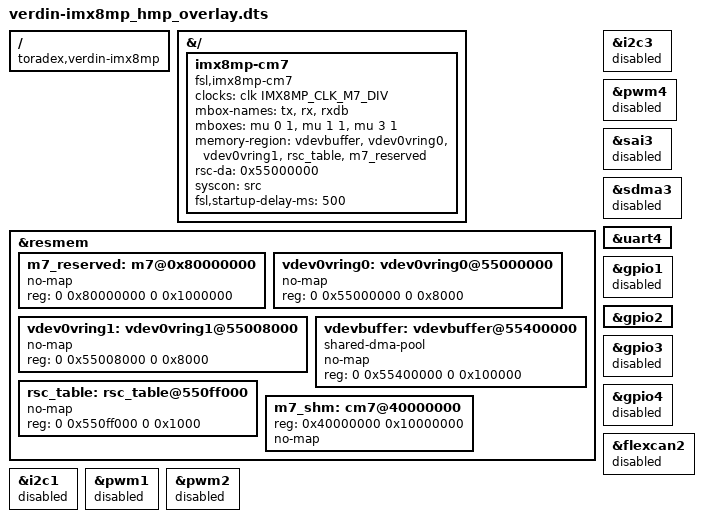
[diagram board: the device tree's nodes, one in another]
// SPDX-License-Identifier: GPL-2.0-or-later OR MIT
/*
 * Copyright 2023 Toradex
 */

/* Enable RPMSG and the RemoteProc M7 driver.
 * Note: This overlay is working only on nonwifi modules. For more information, please
 * check the Verdin iMX8MP Datasheet section 5.4 Wi-Fi and Bluetooth.
 */

/dts-v1/;
/plugin/;

#include <dt-bindings/clock/imx8mp-clock.h>

/ {
	compatible = "toradex,verdin-imx8mp";
};

&{/} {
	imx8mp-cm7 {
		compatible = "fsl,imx8mp-cm7";
		clocks = <&clk IMX8MP_CLK_M7_DIV>;
		mbox-names = "tx", "rx", "rxdb";
		mboxes = <&mu 0 1
			  &mu 1 1
			  &mu 3 1>;
		memory-region = <&vdevbuffer>, <&vdev0vring0>, <&vdev0vring1>, <&rsc_table>, <&m7_reserved>;
		rsc-da = <0x55000000>;
		syscon = <&src>;
		fsl,startup-delay-ms = <500>;
	};
};

&resmem {
	#address-cells = <2>;
	#size-cells = <2>;

	m7_reserved: m7@0x80000000 {
		no-map;
		reg = <0 0x80000000 0 0x1000000>;
	};

	vdev0vring0: vdev0vring0@55000000 {
		no-map;
		reg = <0 0x55000000 0 0x8000>;
	};

	vdev0vring1: vdev0vring1@55008000 {
		no-map;
		reg = <0 0x55008000 0 0x8000>;
	};

	vdevbuffer: vdevbuffer@55400000 {
		compatible = "shared-dma-pool";
		no-map;
		reg = <0 0x55400000 0 0x100000>;
	};

	rsc_table: rsc_table@550ff000 {
		no-map;
		reg = <0 0x550ff000 0 0x1000>;
	};

	m7_shm: cm7@40000000 {
		reg = <0x40000000 0x10000000>;
		no-map;
	};

};

&i2c3 {
	status = "disabled";
};

&pwm4 {
	status = "disabled";
};

&sai3 {
	status = "disabled";
};

&sdma3 {
	status = "disabled";
};

&uart4 {
	status = "okay";
};

&gpio1{
	status = "disabled";
};

&gpio2{
	status = "okay";
};

&gpio3{
	status = "disabled";
};

&gpio4{
	status = "disabled";
};

&flexcan2 {
	status = "disabled";
};

&i2c1{
	status = "disabled";
};

&pwm1{
	status = "disabled";
};

&pwm2{
	status = "disabled";
};
